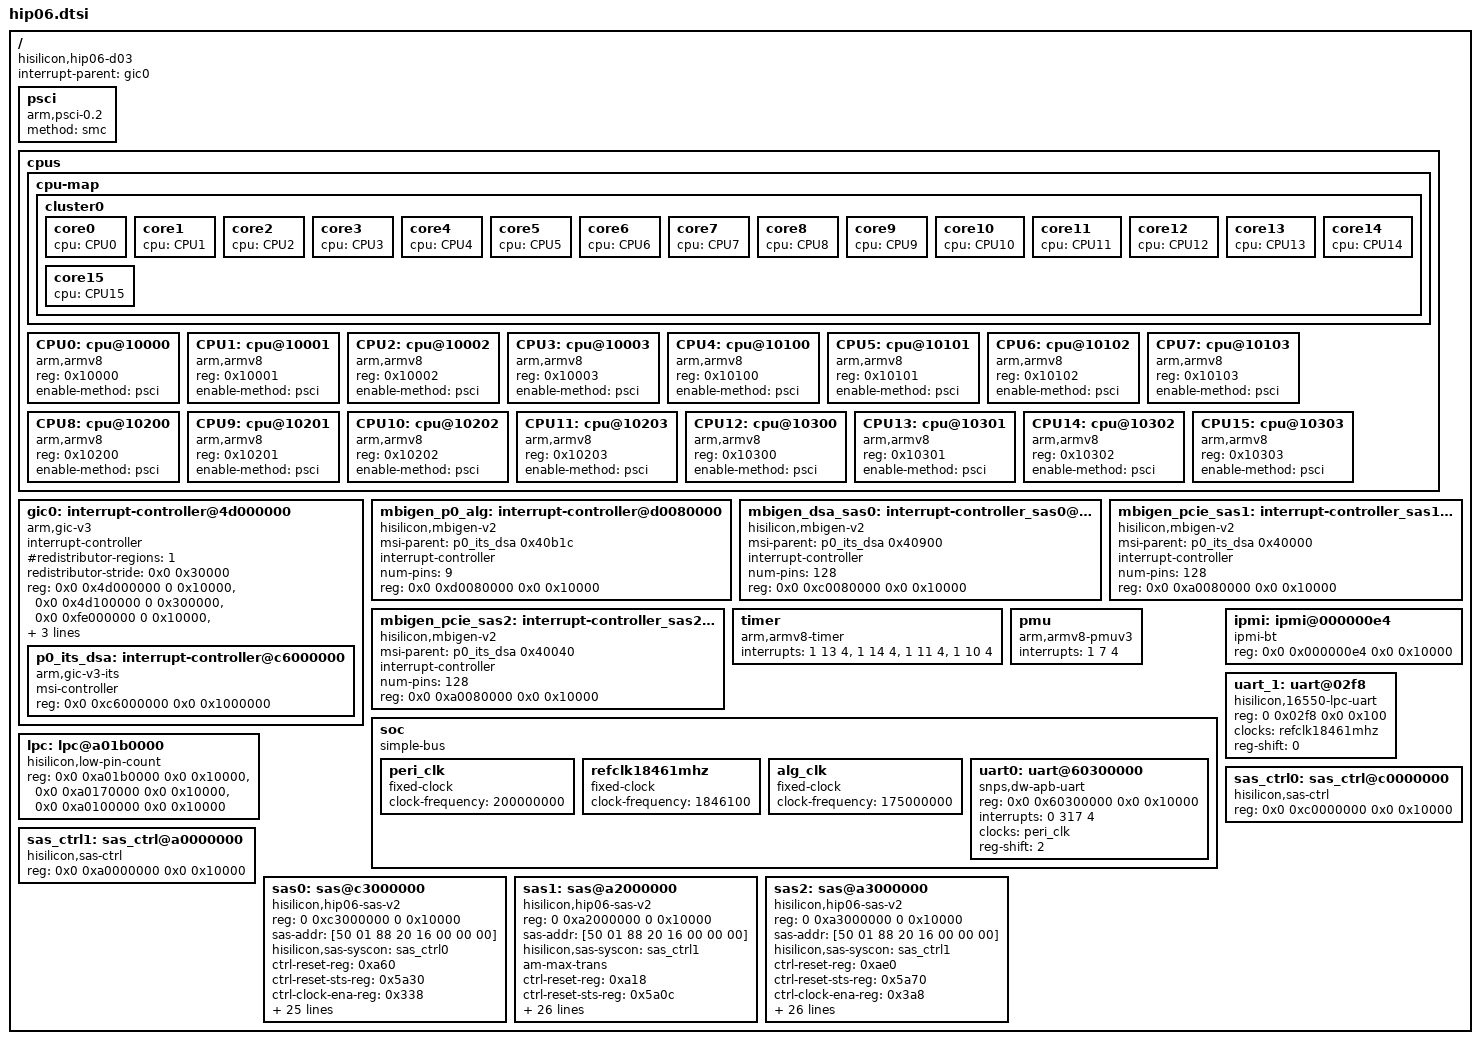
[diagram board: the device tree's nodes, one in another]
/**
 * dts file for Hisilicon D03 Development Board
 *
 * Copyright (C) 2014,2015 Hisilicon Ltd.
 *
 * This program is free software; you can redistribute it and/or modify
 * it under the terms of the GNU General Public License version 2 as
 * publishhed by the Free Software Foundation.
 *
 */

/ {
	#address-cells = <2>;
	#size-cells = <2>;
	compatible = "hisilicon,hip06-d03";
	interrupt-parent = <&gic0>;

	psci {
		compatible = "arm,psci-0.2";
		method = "smc";
	};

	cpus {
		#address-cells = <1>;
		#size-cells = <0>;

		cpu-map {
			cluster0 {
				core0 {
					cpu = <&CPU0>;
				};

				core1 {
					cpu = <&CPU1>;
				};

				core2 {
					cpu = <&CPU2>;
				};

				core3 {
					cpu = <&CPU3>;
				};

				core4 {
					cpu = <&CPU4>;
				};

				core5 {
					cpu = <&CPU5>;
				};

				core6 {
					cpu = <&CPU6>;
				};

				core7 {
					cpu = <&CPU7>;
				};

				core8 {
					cpu = <&CPU8>;
				};

				core9 {
					cpu = <&CPU9>;
				};

				core10 {
					cpu = <&CPU10>;
				};

				core11 {
					cpu = <&CPU11>;
				};

				core12 {
					cpu = <&CPU12>;
				};

				core13 {
					cpu = <&CPU13>;
				};

				core14 {
					cpu = <&CPU14>;
				};

				core15 {
					cpu = <&CPU15>;
				};
			};
		};

		CPU0: cpu@10000 {
			device_type = "cpu";
			compatible = "arm,armv8";
			reg = <0x10000>;
			enable-method = "psci";
		};

		CPU1: cpu@10001 {
			device_type = "cpu";
			compatible = "arm,armv8";
			reg = <0x10001>;
			enable-method = "psci";
		};

		CPU2: cpu@10002 {
			device_type = "cpu";
			compatible = "arm,armv8";
			reg = <0x10002>;
			enable-method = "psci";
		};

		CPU3: cpu@10003 {
			device_type = "cpu";
			compatible = "arm,armv8";
			reg = <0x10003>;
			enable-method = "psci";
		};

		CPU4: cpu@10100 {
			device_type = "cpu";
			compatible = "arm,armv8";
			reg = <0x10100>;
			enable-method = "psci";
		};

		CPU5: cpu@10101 {
			device_type = "cpu";
			compatible = "arm,armv8";
			reg = <0x10101>;
			enable-method = "psci";
		};

		CPU6: cpu@10102 {
			device_type = "cpu";
			compatible = "arm,armv8";
			reg = <0x10102>;
			enable-method = "psci";
		};

		CPU7: cpu@10103 {
			device_type = "cpu";
			compatible = "arm,armv8";
			reg = <0x10103>;
			enable-method = "psci";
		};

		CPU8: cpu@10200 {
			device_type = "cpu";
			compatible = "arm,armv8";
			reg = <0x10200>;
			enable-method = "psci";
		};

		CPU9: cpu@10201 {
			device_type = "cpu";
			compatible = "arm,armv8";
			reg = <0x10201>;
			enable-method = "psci";
		};

		CPU10: cpu@10202 {
			device_type = "cpu";
			compatible = "arm,armv8";
			reg = <0x10202>;
			enable-method = "psci";
		};

		CPU11: cpu@10203 {
			device_type = "cpu";
			compatible = "arm,armv8";
			reg = <0x10203>;
			enable-method = "psci";
		};

		CPU12: cpu@10300 {
			device_type = "cpu";
			compatible = "arm,armv8";
			reg = <0x10300>;
			enable-method = "psci";
		};

		CPU13: cpu@10301 {
			device_type = "cpu";
			compatible = "arm,armv8";
			reg = <0x10301>;
			enable-method = "psci";
		};

		CPU14: cpu@10302 {
			device_type = "cpu";
			compatible = "arm,armv8";
			reg = <0x10302>;
			enable-method = "psci";
		};

		CPU15: cpu@10303 {
			device_type = "cpu";
			compatible = "arm,armv8";
			reg = <0x10303>;
			enable-method = "psci";
		};
	};

	gic0: interrupt-controller@4d000000 {
		compatible = "arm,gic-v3";
		#interrupt-cells = <3>;
		#address-cells = <2>;
		#size-cells = <2>;
		ranges;
		interrupt-controller;
		#redistributor-regions = <1>;
		redistributor-stride = <0x0 0x30000>;
		reg = <0x0 0x4d000000 0 0x10000>,	/* GICD */
		      <0x0 0x4d100000 0 0x300000>,	/* GICR */
		      <0x0 0xfe000000 0 0x10000>,	/* GICC */
		      <0x0 0xfe010000 0 0x10000>,	/* GICH */
		      <0x0 0xfe020000 0 0x10000>;	/* GICV */

		interrupts = <1 9 0xff04>;

		p0_its_dsa: interrupt-controller@c6000000 {
			compatible = "arm,gic-v3-its";
			msi-controller;
			#msi-cells = <1>;
			reg = <0x0 0xc6000000 0x0 0x1000000>;
		};
	};

	mbigen_p0_alg: interrupt-controller@d0080000 {
		compatible = "hisilicon,mbigen-v2";
		msi-parent = <&p0_its_dsa 0x40b1c>;
		interrupt-controller;
		#interrupt-cells = <2>;
		num-pins = <9>;
		reg = <0x0 0xd0080000 0x0 0x10000>;
	};

	mbigen_dsa_sas0: interrupt-controller_sas0@c0080000 {
		compatible = "hisilicon,mbigen-v2";
		msi-parent = <&p0_its_dsa 0x40900>;
		interrupt-controller;
		#interrupt-cells = <2>;
		num-pins = <128>;
		reg = <0x0 0xc0080000 0x0 0x10000>;
	};

	mbigen_pcie_sas1: interrupt-controller_sas1@a0080000 {
		compatible = "hisilicon,mbigen-v2";
		msi-parent = <&p0_its_dsa 0x40000>;
		interrupt-controller;
		#interrupt-cells = <2>;
		num-pins = <128>;
		reg = <0x0 0xa0080000 0x0 0x10000>;
	};

	mbigen_pcie_sas2: interrupt-controller_sas2@a0080000 {
		compatible = "hisilicon,mbigen-v2";
		msi-parent = <&p0_its_dsa 0x40040>;
		interrupt-controller;
		#interrupt-cells = <2>;
		num-pins = <128>;
		reg = <0x0 0xa0080000 0x0 0x10000>;
	};

	timer {
		compatible = "arm,armv8-timer";
		interrupts = <1 13 4>,
			     <1 14 4>,
			     <1 11 4>,
			     <1 10 4>;
	};

	pmu {
		compatible = "arm,armv8-pmuv3";
		interrupts = <1 7 4>;
	};

	soc {
		compatible = "simple-bus";
		#address-cells = <2>;
		#size-cells = <2>;
		ranges = <0x0 0x0 0x0 0x0 0xfff 0xffffffff>;

		peri_clk: peri_clk {
			compatible = "fixed-clock";
			#clock-cells = <0>;
			clock-frequency = <200000000>;
		};

		refclk18461mhz: refclk18461mhz {
			compatible = "fixed-clock";
			#clock-cells = <0>;
			clock-frequency = <1846100>;
		};

		alg_clk: alg_clk {
			compatible = "fixed-clock";
			#clock-cells = <0>;
			clock-frequency = <175000000>;
		};

		uart0: uart@60300000 {
			compatible = "snps,dw-apb-uart";
			reg = <0x0 0x60300000 0x0 0x10000>;
			interrupts = <0 317 4>;
			clocks = <&peri_clk>;
			clock-names = "apb_pclk";
			reg-shift = <2>;
		};
	};

	lpc: lpc@a01b0000 {
		compatible = "hisilicon,low-pin-count";
		reg = <0x0 0xa01b0000 0x0 0x10000>,
		      <0x0 0xa0170000 0x0 0x10000>,
		      <0x0 0xa0100000 0x0 0x10000>;
	};

	ipmi: ipmi@000000e4{
		device_type = "ipmi";
		compatible = "ipmi-bt";
		reg = <0x0 0x000000e4 0x0 0x10000>;
	};

	uart_1: uart@02f8 {
		compatible = "hisilicon,16550-lpc-uart";
		reg = <0 0x02f8 0x0 0x100>;
		clocks = <&refclk18461mhz>;
		clock-names = "clk";
		reg-shift = <0>;
	};
	sas_ctrl0: sas_ctrl@c0000000 {
		compatible = "hisilicon,sas-ctrl", "syscon";
		reg = <0x0 0xc0000000 0x0 0x10000>;
	};

	sas_ctrl1: sas_ctrl@a0000000 {
		compatible = "hisilicon,sas-ctrl", "syscon";
		reg = <0x0 0xa0000000 0x0 0x10000>;
	};

	sas0: sas@c3000000 {
		compatible = "hisilicon,hip06-sas-v2";
		reg = <0 0xc3000000 0 0x10000>;
		sas-addr = [50 01 88 20 16 00 00 00];
		hisilicon,sas-syscon = <&sas_ctrl0>;
		ctrl-reset-reg = <0xa60>;
		ctrl-reset-sts-reg = <0x5a30>;
		ctrl-clock-ena-reg = <0x338>;
		queue-count = <16>;
		phy-count = <8>;
		dma-coherent;
		interrupt-parent = <&mbigen_dsa_sas0>;
		interrupts = <64 1>,
		<65 1>,
		<66 1>,
		<67 1>,
		<68 1>,
		<69 1>,
		<70 1>,
		<71 1>,
		<72 1>,
		<73 1>,
		<75 1>,
		<76 1>,
		<77 1>,
		<78 1>,
		<79 1>,
		<80 1>,
		<81 1>,
		<82 1>,
		<83 1>,
		<84 1>,
		<85 1>,
		<86 1>,
		<87 1>,
		<88 1>,
		<89 1>,
		<90 1>,
		<91 1>,
		<92 1>,
		<93 1>,
		<94 1>,
		<95 1>,
		<96 1>,
		<97 1>,
		<98 1>,
		<99 1>,
		<100 1>,
		<101 1>,
		<102 1>,
		<103 1>,
		<104 1>,
		<105 1>,
		<106 1>,
		<107 1>,
		<108 1>,
		<109 1>,
		<110 1>,
		<111 1>,
		<112 1>,
		<113 1>,
		<114 1>,
		<115 1>,
		<116 1>,
		<117 1>,
		<118 1>,
		<119 1>,
		<120 1>,
		<121 1>,
		<122 1>,
		<123 1>,
		<124 1>,
		<125 1>,
		<126 1>,
		<127 1>,
		<128 1>,
		<129 1>,
		<130 1>,
		<131 1>,
		<132 1>,
		<133 1>,
		<134 1>,
		<135 1>,
		<136 1>,
		<137 1>,
		<138 1>,
		<139 1>,
		<140 1>,
		<141 1>,
		<142 1>,
		<143 1>,
		<144 1>,
		<145 1>,
		<146 1>,
		<147 1>,
		<148 1>,
		<149 1>,
		<150 1>,
		<151 1>,
		<152 1>,
		<153 1>,
		<154 1>,
		<155 1>,
		<156 1>,
		<157 1>,
		<158 1>,
		<159 1>,
		<160 1>,
		<601 4>,
		<602 4>,
		<603 4>,
		<604 4>,
		<605 4>,
		<606 4>,
		<607 4>,
		<608 4>,
		<609 4>,
		<610 4>,
		<611 4>,
		<612 4>,
		<613 4>,
		<614 4>,
		<615 4>,
		<616 4>,
		<617 4>,
		<618 4>,
		<619 4>,
		<620 4>,
		<621 4>,
		<622 4>,
		<623 4>,
		<624 4>,
		<625 4>,
		<626 4>,
		<627 4>,
		<628 4>,
		<629 4>,
		<630 4>,
		<631 4>,
		<632 4>;
		status = "okay";
	};

	sas1: sas@a2000000 {
		compatible = "hisilicon,hip06-sas-v2";
		reg = <0 0xa2000000 0 0x10000>;
		sas-addr = [50 01 88 20 16 00 00 00];
		hisilicon,sas-syscon = <&sas_ctrl1>;
		am-max-trans;
		ctrl-reset-reg = <0xa18>;
		ctrl-reset-sts-reg = <0x5a0c>;
		ctrl-clock-ena-reg = <0x318>;
		queue-count = <16>;
		phy-count = <8>;
		dma-coherent;
		interrupt-parent = <&mbigen_pcie_sas1>;
		interrupts = <64 1>,
		<65 1>,
		<66 1>,
		<67 1>,
		<68 1>,
		<69 1>,
		<70 1>,
		<71 1>,
		<72 1>,
		<73 1>,
		<75 1>,
		<76 1>,
		<77 1>,
		<78 1>,
		<79 1>,
		<80 1>,
		<81 1>,
		<82 1>,
		<83 1>,
		<84 1>,
		<85 1>,
		<86 1>,
		<87 1>,
		<88 1>,
		<89 1>,
		<90 1>,
		<91 1>,
		<92 1>,
		<93 1>,
		<94 1>,
		<95 1>,
		<96 1>,
		<97 1>,
		<98 1>,
		<99 1>,
		<100 1>,
		<101 1>,
		<102 1>,
		<103 1>,
		<104 1>,
		<105 1>,
		<106 1>,
		<107 1>,
		<108 1>,
		<109 1>,
		<110 1>,
		<111 1>,
		<112 1>,
		<113 1>,
		<114 1>,
		<115 1>,
		<116 1>,
		<117 1>,
		<118 1>,
		<119 1>,
		<120 1>,
		<121 1>,
		<122 1>,
		<123 1>,
		<124 1>,
		<125 1>,
		<126 1>,
		<127 1>,
		<128 1>,
		<129 1>,
		<130 1>,
		<131 1>,
		<132 1>,
		<133 1>,
		<134 1>,
		<135 1>,
		<136 1>,
		<137 1>,
		<138 1>,
		<139 1>,
		<140 1>,
		<141 1>,
		<142 1>,
		<143 1>,
		<144 1>,
		<145 1>,
		<146 1>,
		<147 1>,
		<148 1>,
		<149 1>,
		<150 1>,
		<151 1>,
		<152 1>,
		<153 1>,
		<154 1>,
		<155 1>,
		<156 1>,
		<157 1>,
		<158 1>,
		<159 1>,
		<160 1>,
		<576 4>,
		<577 4>,
		<578 4>,
		<579 4>,
		<580 4>,
		<581 4>,
		<582 4>,
		<583 4>,
		<584 4>,
		<585 4>,
		<586 4>,
		<587 4>,
		<588 4>,
		<589 4>,
		<590 4>,
		<591 4>,
		<592 4>,
		<593 4>,
		<594 4>,
		<595 4>,
		<596 4>,
		<597 4>,
		<598 4>,
		<599 4>,
		<600 4>,
		<601 4>,
		<602 4>,
		<603 4>,
		<604 4>,
		<605 4>,
		<606 4>,
		<607 4>;
		status = "okay";
	};

	sas2: sas@a3000000 {
		compatible = "hisilicon,hip06-sas-v2";
		reg = <0 0xa3000000 0 0x10000>;
		sas-addr = [50 01 88 20 16 00 00 00];
		hisilicon,sas-syscon = <&sas_ctrl1>;
		ctrl-reset-reg = <0xae0>;
		ctrl-reset-sts-reg = <0x5a70>;
		ctrl-clock-ena-reg = <0x3a8>;
		queue-count = <16>;
		phy-count = <8>;
		dma-coherent;
		interrupt-parent = <&mbigen_pcie_sas2>;
		interrupts = <192 1>,
		<193 1>,
		<194 1>,
		<195 1>,
		<196 1>,
		<197 1>,
		<198 1>,
		<199 1>,
		<200 1>,
		<201 1>,
		<202 1>,
		<203 1>,
		<204 1>,
		<205 1>,
		<206 1>,
		<207 1>,
		<208 1>,
		<209 1>,
		<210 1>,
		<211 1>,
		<212 1>,
		<213 1>,
		<214 1>,
		<215 1>,
		<216 1>,
		<217 1>,
		<218 1>,
		<219 1>,
		<220 1>,
		<221 1>,
		<222 1>,
		<223 1>,
		<224 1>,
		<225 1>,
		<226 1>,
		<227 1>,
		<228 1>,
		<229 1>,
		<230 1>,
		<231 1>,
		<232 1>,
		<233 1>,
		<234 1>,
		<235 1>,
		<236 1>,
		<237 1>,
		<238 1>,
		<239 1>,
		<240 1>,
		<241 1>,
		<242 1>,
		<243 1>,
		<244 1>,
		<245 1>,
		<246 1>,
		<247 1>,
		<248 1>,
		<249 1>,
		<250 1>,
		<251 1>,
		<252 1>,
		<253 1>,
		<254 1>,
		<255 1>,
		<256 1>,
		<257 1>,
		<258 1>,
		<259 1>,
		<260 1>,
		<261 1>,
		<262 1>,
		<263 1>,
		<264 1>,
		<265 1>,
		<266 1>,
		<267 1>,
		<268 1>,
		<269 1>,
		<270 1>,
		<271 1>,
		<272 1>,
		<273 1>,
		<274 1>,
		<275 1>,
		<276 1>,
		<277 1>,
		<278 1>,
		<279 1>,
		<280 1>,
		<281 1>,
		<282 1>,
		<283 1>,
		<284 1>,
		<285 1>,
		<286 1>,
		<287 1>,
		<608 4>,
		<609 4>,
		<610 4>,
		<611 4>,
		<612 4>,
		<613 4>,
		<614 4>,
		<615 4>,
		<616 4>,
		<617 4>,
		<618 4>,
		<619 4>,
		<620 4>,
		<621 4>,
		<622 4>,
		<623 4>,
		<624 4>,
		<625 4>,
		<626 4>,
		<627 4>,
		<628 4>,
		<629 4>,
		<630 4>,
		<631 4>,
		<632 4>,
		<633 4>,
		<634 4>,
		<635 4>,
		<636 4>,
		<637 4>,
		<638 4>,
		<639 4>;
		status = "ok";
	};

};
